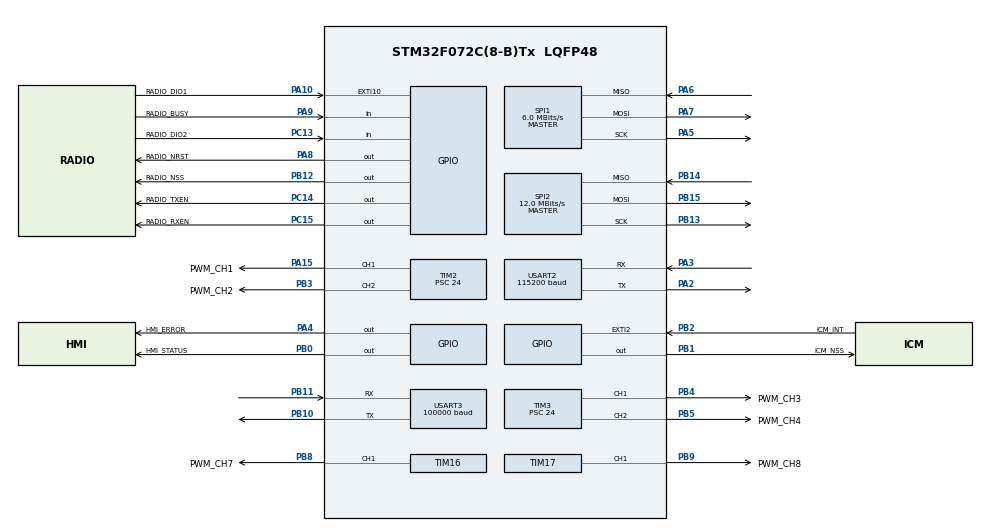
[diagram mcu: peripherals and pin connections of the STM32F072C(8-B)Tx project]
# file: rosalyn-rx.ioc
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Mcu.Family=STM32F0
Mcu.Name=STM32F072C(8-B)Tx
Mcu.Package=LQFP48
NVIC.EXTI2_3_IRQn=true\:0\:0\:false\:false\:false\:true\:false
NVIC.EXTI4_15_IRQn=true\:0\:0\:false\:false\:false\:true\:false
NVIC.TIM7_IRQn=true\:0\:0\:false\:false\:false\:true\:false
NVIC.USART2_IRQn=true\:0\:0\:false\:false\:false\:true\:false
NVIC.USART3_4_IRQn=true\:0\:0\:false\:false\:false\:true\:false
PA10.GPIO_Label=RADIO_DIO1
PA10.GPIO_PuPd=GPIO_NOPULL
PA10.Signal=GPXTI10
PA13.Mode=Serial_Wire
PA13.Signal=SYS_SWDIO
PA14.Mode=Serial_Wire
PA14.Signal=SYS_SWCLK
PA15.GPIO_Label=PWM_CH1
PA15.Signal=S_TIM2_CH1_ETR
PA2.Mode=Asynchronous
PA2.Signal=USART2_TX
PA3.GPIO_PuPd=GPIO_PULLUP
PA3.Mode=Asynchronous
PA3.Signal=USART2_RX
PA4.GPIO_Label=HMI_ERROR
PA4.PinState=GPIO_PIN_SET
PA4.Signal=GPIO_Output
PA5.Mode=Full_Duplex_Master
PA5.Signal=SPI1_SCK
PA6.GPIO_PuPd=GPIO_PULLUP
PA6.Mode=Full_Duplex_Master
PA6.Signal=SPI1_MISO
PA7.Mode=Full_Duplex_Master
PA7.Signal=SPI1_MOSI
PA8.GPIO_Label=RADIO_NRST
PA8.PinState=GPIO_PIN_SET
PA8.Signal=GPIO_Output
PA9.GPIO_Label=RADIO_BUSY
PA9.GPIO_PuPd=GPIO_NOPULL
PA9.Signal=GPIO_Input
PB0.GPIO_Label=HMI_STATUS
PB0.PinState=GPIO_PIN_SET
PB0.Signal=GPIO_Output
PB1.GPIO_Label=ICM_NSS
PB1.PinState=GPIO_PIN_SET
PB1.Signal=GPIO_Output
PB10.Mode=Asynchronous
PB10.Signal=USART3_TX
PB11.GPIO_PuPd=GPIO_PULLUP
PB11.Mode=Asynchronous
PB11.Signal=USART3_RX
PB12.GPIO_Label=RADIO_NSS
PB12.PinState=GPIO_PIN_SET
PB12.Signal=GPIO_Output
PB13.Mode=Full_Duplex_Master
PB13.Signal=SPI2_SCK
PB14.GPIO_PuPd=GPIO_PULLUP
PB14.Mode=Full_Duplex_Master
PB14.Signal=SPI2_MISO
PB15.Mode=Full_Duplex_Master
PB15.Signal=SPI2_MOSI
PB2.GPIO_Label=ICM_INT
PB2.GPIO_PuPd=GPIO_PULLDOWN
PB2.Signal=GPXTI2
PB3.GPIO_Label=PWM_CH2
PB3.Signal=S_TIM2_CH2
PB4.GPIO_Label=PWM_CH3
PB4.Signal=S_TIM3_CH1
PB5.GPIO_Label=PWM_CH4
PB5.Signal=S_TIM3_CH2
PB8.GPIO_Label=PWM_CH7
PB8.Signal=S_TIM16_CH1
PB9.GPIO_Label=PWM_CH8
PB9.Signal=S_TIM17_CH1
PC13.GPIO_Label=RADIO_DIO2
PC13.GPIO_PuPd=GPIO_NOPULL
PC13.Signal=GPIO_Input
PC14-OSC32_IN.GPIO_Label=RADIO_TXEN
PC14-OSC32_IN.Signal=GPIO_Output
PC15-OSC32_OUT.GPIO_Label=RADIO_RXEN
PC15-OSC32_OUT.Signal=GPIO_Output
ProjectManager.HeapSize=0x200
ProjectManager.StackSize=0x400
ProjectManager.TargetToolchain=STM32CubeIDE
RCC.AHBFreq_Value=48000000
RCC.APB1Freq_Value=48000000
RCC.APB1TimFreq_Value=48000000
RCC.HCLKFreq_Value=48000000
RCC.SYSCLKFreq_VALUE=48000000
RCC.SYSCLKSource=RCC_SYSCLKSOURCE_HSI48
SH.S_TIM16_CH1.0=TIM16_CH1,PWM Generation1 CH1
SH.S_TIM17_CH1.0=TIM17_CH1,PWM Generation1 CH1
SH.S_TIM2_CH1_ETR.0=TIM2_CH1,PWM Generation1 CH1
SH.S_TIM2_CH2.0=TIM2_CH2,PWM Generation2 CH2
SH.S_TIM3_CH1.0=TIM3_CH1,PWM Generation1 CH1
SH.S_TIM3_CH2.0=TIM3_CH2,PWM Generation2 CH2
SPI1.BaudRatePrescaler=SPI_BAUDRATEPRESCALER_8
SPI1.CalculateBaudRate=6.0 MBits/s
SPI1.DataSize=SPI_DATASIZE_8BIT
SPI1.Direction=SPI_DIRECTION_2LINES
SPI1.Mode=SPI_MODE_MASTER
SPI1.VirtualType=VM_MASTER
SPI2.BaudRatePrescaler=SPI_BAUDRATEPRESCALER_4
SPI2.CalculateBaudRate=12.0 MBits/s
SPI2.DataSize=SPI_DATASIZE_8BIT
SPI2.Direction=SPI_DIRECTION_2LINES
SPI2.Mode=SPI_MODE_MASTER
SPI2.VirtualType=VM_MASTER
TIM16.AutomaticOutput=TIM_AUTOMATICOUTPUT_ENABLE
TIM16.Channel=TIM_CHANNEL_1
TIM16.Period=39999
TIM16.Prescaler=24
TIM16.Pulse=0
TIM17.AutomaticOutput=TIM_AUTOMATICOUTPUT_ENABLE
TIM17.Channel=TIM_CHANNEL_1
TIM17.OffStateIDLEMode=TIM_OSSI_DISABLE
TIM17.Period=39999
TIM17.Prescaler=24
TIM17.Pulse=0
TIM2.Channel-PWM\ Generation1\ CH1=TIM_CHANNEL_1
TIM2.Channel-PWM\ Generation2\ CH2=TIM_CHANNEL_2
TIM2.Period=39999
TIM2.Prescaler=24
TIM2.Pulse-PWM\ Generation1\ CH1=0
TIM2.Pulse-PWM\ Generation2\ CH2=0
TIM3.Channel-PWM\ Generation1\ CH1=TIM_CHANNEL_1
TIM3.Channel-PWM\ Generation2\ CH2=TIM_CHANNEL_2
TIM3.Period=39999
TIM3.Prescaler=24
TIM3.Pulse-PWM\ Generation1\ CH1=0
TIM3.Pulse-PWM\ Generation2\ CH2=0
TIM7.Period=30000
TIM7.Prescaler=48
USART2.BaudRate=115200
USART2.VirtualMode-Asynchronous=VM_ASYNC
USART3.BaudRate=100000
USART3.Parity=PARITY_EVEN
USART3.RxPinLevelInvertParam=ADVFEATURE_RXINV_ENABLE
USART3.StopBits=STOPBITS_2
USART3.TxPinLevelInvertParam=ADVFEATURE_TXINV_ENABLE
USART3.VirtualMode-Asynchronous=VM_ASYNC
USART3.WordLength=WORDLENGTH_9B
VP_CRC_VS_CRC.Mode=CRC_Activate
VP_TIM16_VS_ClockSourceINT.Mode=Enable_Timer
VP_TIM17_VS_ClockSourceINT.Mode=Enable_Timer
VP_TIM2_VS_ClockSourceINT.Mode=Internal
VP_TIM3_VS_ClockSourceINT.Mode=Internal
VP_TIM7_VS_ClockSourceINT.Mode=Enable_Timer
board=custom

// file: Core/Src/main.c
/* USER CODE BEGIN Header */
/**
  ******************************************************************************
  * @file           : main.c
  * @brief          : Main program body
  ******************************************************************************
  * @attention
  *
  * <h2><center>&copy; Copyright (c) 2020 STMicroelectronics.
  * All rights reserved.</center></h2>
  *
  * This software component is licensed by ST under BSD 3-Clause license,
  * the "License"; You may not use this file except in compliance with the
  * License. You may obtain a copy of the License at:
  *                        opensource.org/licenses/BSD-3-Clause
  *
  ******************************************************************************
  */
/* USER CODE END Header */
#include "main.h"

void SystemClock_Config(void);
static void MX_GPIO_Init(void);
static void MX_SPI2_Init(void);
static void MX_CRC_Init(void);
static void MX_SPI1_Init(void);
static void MX_USART2_UART_Init(void);
static void MX_USART3_UART_Init(void);
static void MX_TIM2_Init(void);
static void MX_TIM3_Init(void);
static void MX_TIM16_Init(void);
static void MX_TIM17_Init(void);
static void MX_TIM7_Init(void);

int main(void)
{

  /* MCU Configuration--------------------------------------------------------*/

  /* Reset of all peripherals, Initializes the Flash interface and the Systick. */

  LL_APB1_GRP2_EnableClock(LL_APB1_GRP2_PERIPH_SYSCFG);
  LL_APB1_GRP1_EnableClock(LL_APB1_GRP1_PERIPH_PWR);

  /* System interrupt init*/

  /* Configure the system clock */
  SystemClock_Config();

  /* Initialize all configured peripherals */
  MX_GPIO_Init();
  MX_SPI2_Init();
  MX_CRC_Init();
  MX_SPI1_Init();
  MX_USART2_UART_Init();
  MX_USART3_UART_Init();
  MX_TIM2_Init();
  MX_TIM3_Init();
  MX_TIM16_Init();
  MX_TIM17_Init();
  MX_TIM7_Init();
  /* USER CODE BEGIN 2 */
  extern void RosalynRxSetup( void );
  RosalynRxSetup();
  /* USER CODE END 2 */

  /* Infinite loop */
  while (1)
  {

    /* USER CODE BEGIN 3 */
    extern void RosalynRxLoop( void );
    RosalynRxLoop();
  }
  /* USER CODE END 3 */
}

void SystemClock_Config(void)
{
  LL_FLASH_SetLatency(LL_FLASH_LATENCY_1);
  while(LL_FLASH_GetLatency() != LL_FLASH_LATENCY_1)
  {
  }
  LL_RCC_HSI48_Enable();

   /* Wait till HSI48 is ready */
  while(LL_RCC_HSI48_IsReady() != 1)
  {

  }
  LL_RCC_SetAHBPrescaler(LL_RCC_SYSCLK_DIV_1);
  LL_RCC_SetAPB1Prescaler(LL_RCC_APB1_DIV_1);
  LL_RCC_SetSysClkSource(LL_RCC_SYS_CLKSOURCE_HSI48);

   /* Wait till System clock is ready */
  while(LL_RCC_GetSysClkSource() != LL_RCC_SYS_CLKSOURCE_STATUS_HSI48)
  {

  }
  LL_Init1msTick(48000000);
  LL_SetSystemCoreClock(48000000);
  LL_RCC_SetUSARTClockSource(LL_RCC_USART2_CLKSOURCE_PCLK1);
}

static void MX_CRC_Init(void)
{

  /* Peripheral clock enable */
  LL_AHB1_GRP1_EnableClock(LL_AHB1_GRP1_PERIPH_CRC);

  LL_CRC_SetInputDataReverseMode(CRC, LL_CRC_INDATA_REVERSE_NONE);
  LL_CRC_SetOutputDataReverseMode(CRC, LL_CRC_OUTDATA_REVERSE_NONE);
  LL_CRC_SetInitialData(CRC, LL_CRC_DEFAULT_CRC_INITVALUE);

}

static void MX_SPI1_Init(void)
{

  LL_SPI_InitTypeDef SPI_InitStruct = {0};

  LL_GPIO_InitTypeDef GPIO_InitStruct = {0};

  /* Peripheral clock enable */
  LL_APB1_GRP2_EnableClock(LL_APB1_GRP2_PERIPH_SPI1);

  LL_AHB1_GRP1_EnableClock(LL_AHB1_GRP1_PERIPH_GPIOA);
  /**SPI1 GPIO Configuration
  PA5   ------> SPI1_SCK
  PA6   ------> SPI1_MISO
  PA7   ------> SPI1_MOSI
  */
  GPIO_InitStruct.Pin = LL_GPIO_PIN_5;
  GPIO_InitStruct.Mode = LL_GPIO_MODE_ALTERNATE;
  GPIO_InitStruct.Speed = LL_GPIO_SPEED_FREQ_HIGH;
  GPIO_InitStruct.OutputType = LL_GPIO_OUTPUT_PUSHPULL;
  GPIO_InitStruct.Pull = LL_GPIO_PULL_NO;
  GPIO_InitStruct.Alternate = LL_GPIO_AF_0;
  LL_GPIO_Init(GPIOA, &GPIO_InitStruct);

  GPIO_InitStruct.Pin = LL_GPIO_PIN_6;
  GPIO_InitStruct.Mode = LL_GPIO_MODE_ALTERNATE;
  GPIO_InitStruct.Speed = LL_GPIO_SPEED_FREQ_HIGH;
  GPIO_InitStruct.OutputType = LL_GPIO_OUTPUT_PUSHPULL;
  GPIO_InitStruct.Pull = LL_GPIO_PULL_UP;
  GPIO_InitStruct.Alternate = LL_GPIO_AF_0;
  LL_GPIO_Init(GPIOA, &GPIO_InitStruct);

  GPIO_InitStruct.Pin = LL_GPIO_PIN_7;
  GPIO_InitStruct.Mode = LL_GPIO_MODE_ALTERNATE;
  GPIO_InitStruct.Speed = LL_GPIO_SPEED_FREQ_HIGH;
  GPIO_InitStruct.OutputType = LL_GPIO_OUTPUT_PUSHPULL;
  GPIO_InitStruct.Pull = LL_GPIO_PULL_NO;
  GPIO_InitStruct.Alternate = LL_GPIO_AF_0;
  LL_GPIO_Init(GPIOA, &GPIO_InitStruct);

  /* SPI1 parameter configuration*/
  SPI_InitStruct.TransferDirection = LL_SPI_FULL_DUPLEX;
  SPI_InitStruct.Mode = LL_SPI_MODE_MASTER;
  SPI_InitStruct.DataWidth = LL_SPI_DATAWIDTH_8BIT;
  SPI_InitStruct.ClockPolarity = LL_SPI_POLARITY_LOW;
  SPI_InitStruct.ClockPhase = LL_SPI_PHASE_1EDGE;
  SPI_InitStruct.NSS = LL_SPI_NSS_SOFT;
  SPI_InitStruct.BaudRate = LL_SPI_BAUDRATEPRESCALER_DIV8;
  SPI_InitStruct.BitOrder = LL_SPI_MSB_FIRST;
  SPI_InitStruct.CRCCalculation = LL_SPI_CRCCALCULATION_DISABLE;
  SPI_InitStruct.CRCPoly = 7;
  LL_SPI_Init(SPI1, &SPI_InitStruct);
  LL_SPI_SetStandard(SPI1, LL_SPI_PROTOCOL_MOTOROLA);
  LL_SPI_EnableNSSPulseMgt(SPI1);

}

static void MX_SPI2_Init(void)
{

  LL_SPI_InitTypeDef SPI_InitStruct = {0};

  LL_GPIO_InitTypeDef GPIO_InitStruct = {0};

  /* Peripheral clock enable */
  LL_APB1_GRP1_EnableClock(LL_APB1_GRP1_PERIPH_SPI2);

  LL_AHB1_GRP1_EnableClock(LL_AHB1_GRP1_PERIPH_GPIOB);
  /**SPI2 GPIO Configuration
  PB13   ------> SPI2_SCK
  PB14   ------> SPI2_MISO
  PB15   ------> SPI2_MOSI
  */
  GPIO_InitStruct.Pin = LL_GPIO_PIN_13;
  GPIO_InitStruct.Mode = LL_GPIO_MODE_ALTERNATE;
  GPIO_InitStruct.Speed = LL_GPIO_SPEED_FREQ_HIGH;
  GPIO_InitStruct.OutputType = LL_GPIO_OUTPUT_PUSHPULL;
  GPIO_InitStruct.Pull = LL_GPIO_PULL_NO;
  GPIO_InitStruct.Alternate = LL_GPIO_AF_0;
  LL_GPIO_Init(GPIOB, &GPIO_InitStruct);

  GPIO_InitStruct.Pin = LL_GPIO_PIN_14;
  GPIO_InitStruct.Mode = LL_GPIO_MODE_ALTERNATE;
  GPIO_InitStruct.Speed = LL_GPIO_SPEED_FREQ_HIGH;
  GPIO_InitStruct.OutputType = LL_GPIO_OUTPUT_PUSHPULL;
  GPIO_InitStruct.Pull = LL_GPIO_PULL_UP;
  GPIO_InitStruct.Alternate = LL_GPIO_AF_0;
  LL_GPIO_Init(GPIOB, &GPIO_InitStruct);

  GPIO_InitStruct.Pin = LL_GPIO_PIN_15;
  GPIO_InitStruct.Mode = LL_GPIO_MODE_ALTERNATE;
  GPIO_InitStruct.Speed = LL_GPIO_SPEED_FREQ_HIGH;
  GPIO_InitStruct.OutputType = LL_GPIO_OUTPUT_PUSHPULL;
  GPIO_InitStruct.Pull = LL_GPIO_PULL_NO;
  GPIO_InitStruct.Alternate = LL_GPIO_AF_0;
  LL_GPIO_Init(GPIOB, &GPIO_InitStruct);

  /* SPI2 parameter configuration*/
  SPI_InitStruct.TransferDirection = LL_SPI_FULL_DUPLEX;
  SPI_InitStruct.Mode = LL_SPI_MODE_MASTER;
  SPI_InitStruct.DataWidth = LL_SPI_DATAWIDTH_8BIT;
  SPI_InitStruct.ClockPolarity = LL_SPI_POLARITY_LOW;
  SPI_InitStruct.ClockPhase = LL_SPI_PHASE_1EDGE;
  SPI_InitStruct.NSS = LL_SPI_NSS_SOFT;
  SPI_InitStruct.BaudRate = LL_SPI_BAUDRATEPRESCALER_DIV4;
  SPI_InitStruct.BitOrder = LL_SPI_MSB_FIRST;
  SPI_InitStruct.CRCCalculation = LL_SPI_CRCCALCULATION_DISABLE;
  SPI_InitStruct.CRCPoly = 7;
  LL_SPI_Init(SPI2, &SPI_InitStruct);
  LL_SPI_SetStandard(SPI2, LL_SPI_PROTOCOL_MOTOROLA);
  LL_SPI_EnableNSSPulseMgt(SPI2);

}

static void MX_TIM2_Init(void)
{

  LL_TIM_InitTypeDef TIM_InitStruct = {0};
  LL_TIM_OC_InitTypeDef TIM_OC_InitStruct = {0};

  LL_GPIO_InitTypeDef GPIO_InitStruct = {0};

  /* Peripheral clock enable */
  LL_APB1_GRP1_EnableClock(LL_APB1_GRP1_PERIPH_TIM2);

  TIM_InitStruct.Prescaler = 24;
  TIM_InitStruct.CounterMode = LL_TIM_COUNTERMODE_UP;
  TIM_InitStruct.Autoreload = 39999;
  TIM_InitStruct.ClockDivision = LL_TIM_CLOCKDIVISION_DIV1;
  LL_TIM_Init(TIM2, &TIM_InitStruct);
  LL_TIM_DisableARRPreload(TIM2);
  LL_TIM_SetClockSource(TIM2, LL_TIM_CLOCKSOURCE_INTERNAL);
  LL_TIM_OC_EnablePreload(TIM2, LL_TIM_CHANNEL_CH1);
  TIM_OC_InitStruct.OCMode = LL_TIM_OCMODE_PWM1;
  TIM_OC_InitStruct.OCState = LL_TIM_OCSTATE_DISABLE;
  TIM_OC_InitStruct.OCNState = LL_TIM_OCSTATE_DISABLE;
  TIM_OC_InitStruct.CompareValue = 0;
  TIM_OC_InitStruct.OCPolarity = LL_TIM_OCPOLARITY_HIGH;
  LL_TIM_OC_Init(TIM2, LL_TIM_CHANNEL_CH1, &TIM_OC_InitStruct);
  LL_TIM_OC_DisableFast(TIM2, LL_TIM_CHANNEL_CH1);
  LL_TIM_OC_EnablePreload(TIM2, LL_TIM_CHANNEL_CH2);
  TIM_OC_InitStruct.OCState = LL_TIM_OCSTATE_DISABLE;
  TIM_OC_InitStruct.OCNState = LL_TIM_OCSTATE_DISABLE;
  LL_TIM_OC_Init(TIM2, LL_TIM_CHANNEL_CH2, &TIM_OC_InitStruct);
  LL_TIM_OC_DisableFast(TIM2, LL_TIM_CHANNEL_CH2);
  LL_TIM_SetTriggerOutput(TIM2, LL_TIM_TRGO_RESET);
  LL_TIM_DisableMasterSlaveMode(TIM2);
  LL_AHB1_GRP1_EnableClock(LL_AHB1_GRP1_PERIPH_GPIOA);
  LL_AHB1_GRP1_EnableClock(LL_AHB1_GRP1_PERIPH_GPIOB);
  /**TIM2 GPIO Configuration
  PA15   ------> TIM2_CH1
  PB3   ------> TIM2_CH2
  */
  GPIO_InitStruct.Pin = PWM_CH1_Pin;
  GPIO_InitStruct.Mode = LL_GPIO_MODE_ALTERNATE;
  GPIO_InitStruct.Speed = LL_GPIO_SPEED_FREQ_LOW;
  GPIO_InitStruct.OutputType = LL_GPIO_OUTPUT_PUSHPULL;
  GPIO_InitStruct.Pull = LL_GPIO_PULL_NO;
  GPIO_InitStruct.Alternate = LL_GPIO_AF_2;
  LL_GPIO_Init(PWM_CH1_GPIO_Port, &GPIO_InitStruct);

  GPIO_InitStruct.Pin = PWM_CH2_Pin;
  GPIO_InitStruct.Mode = LL_GPIO_MODE_ALTERNATE;
  GPIO_InitStruct.Speed = LL_GPIO_SPEED_FREQ_LOW;
  GPIO_InitStruct.OutputType = LL_GPIO_OUTPUT_PUSHPULL;
  GPIO_InitStruct.Pull = LL_GPIO_PULL_NO;
  GPIO_InitStruct.Alternate = LL_GPIO_AF_2;
  LL_GPIO_Init(PWM_CH2_GPIO_Port, &GPIO_InitStruct);

}

static void MX_TIM3_Init(void)
{

  LL_TIM_InitTypeDef TIM_InitStruct = {0};
  LL_TIM_OC_InitTypeDef TIM_OC_InitStruct = {0};

  LL_GPIO_InitTypeDef GPIO_InitStruct = {0};

  /* Peripheral clock enable */
  LL_APB1_GRP1_EnableClock(LL_APB1_GRP1_PERIPH_TIM3);

  TIM_InitStruct.Prescaler = 24;
  TIM_InitStruct.CounterMode = LL_TIM_COUNTERMODE_UP;
  TIM_InitStruct.Autoreload = 39999;
  TIM_InitStruct.ClockDivision = LL_TIM_CLOCKDIVISION_DIV1;
  LL_TIM_Init(TIM3, &TIM_InitStruct);
  LL_TIM_DisableARRPreload(TIM3);
  LL_TIM_SetClockSource(TIM3, LL_TIM_CLOCKSOURCE_INTERNAL);
  LL_TIM_OC_EnablePreload(TIM3, LL_TIM_CHANNEL_CH1);
  TIM_OC_InitStruct.OCMode = LL_TIM_OCMODE_PWM1;
  TIM_OC_InitStruct.OCState = LL_TIM_OCSTATE_DISABLE;
  TIM_OC_InitStruct.OCNState = LL_TIM_OCSTATE_DISABLE;
  TIM_OC_InitStruct.CompareValue = 0;
  TIM_OC_InitStruct.OCPolarity = LL_TIM_OCPOLARITY_HIGH;
  LL_TIM_OC_Init(TIM3, LL_TIM_CHANNEL_CH1, &TIM_OC_InitStruct);
  LL_TIM_OC_DisableFast(TIM3, LL_TIM_CHANNEL_CH1);
  LL_TIM_OC_EnablePreload(TIM3, LL_TIM_CHANNEL_CH2);
  TIM_OC_InitStruct.OCState = LL_TIM_OCSTATE_DISABLE;
  TIM_OC_InitStruct.OCNState = LL_TIM_OCSTATE_DISABLE;
  LL_TIM_OC_Init(TIM3, LL_TIM_CHANNEL_CH2, &TIM_OC_InitStruct);
  LL_TIM_OC_DisableFast(TIM3, LL_TIM_CHANNEL_CH2);
  LL_TIM_SetTriggerOutput(TIM3, LL_TIM_TRGO_RESET);
  LL_TIM_DisableMasterSlaveMode(TIM3);
  LL_AHB1_GRP1_EnableClock(LL_AHB1_GRP1_PERIPH_GPIOB);
  /**TIM3 GPIO Configuration
  PB4   ------> TIM3_CH1
  PB5   ------> TIM3_CH2
  */
  GPIO_InitStruct.Pin = PWM_CH3_Pin;
  GPIO_InitStruct.Mode = LL_GPIO_MODE_ALTERNATE;
  GPIO_InitStruct.Speed = LL_GPIO_SPEED_FREQ_LOW;
  GPIO_InitStruct.OutputType = LL_GPIO_OUTPUT_PUSHPULL;
  GPIO_InitStruct.Pull = LL_GPIO_PULL_NO;
  GPIO_InitStruct.Alternate = LL_GPIO_AF_1;
  LL_GPIO_Init(PWM_CH3_GPIO_Port, &GPIO_InitStruct);

  GPIO_InitStruct.Pin = PWM_CH4_Pin;
  GPIO_InitStruct.Mode = LL_GPIO_MODE_ALTERNATE;
  GPIO_InitStruct.Speed = LL_GPIO_SPEED_FREQ_LOW;
  GPIO_InitStruct.OutputType = LL_GPIO_OUTPUT_PUSHPULL;
  GPIO_InitStruct.Pull = LL_GPIO_PULL_NO;
  GPIO_InitStruct.Alternate = LL_GPIO_AF_1;
  LL_GPIO_Init(PWM_CH4_GPIO_Port, &GPIO_InitStruct);

}

static void MX_TIM7_Init(void)
{

  LL_TIM_InitTypeDef TIM_InitStruct = {0};

  /* Peripheral clock enable */
  LL_APB1_GRP1_EnableClock(LL_APB1_GRP1_PERIPH_TIM7);

  /* TIM7 interrupt Init */
  NVIC_SetPriority(TIM7_IRQn, 0);
  NVIC_EnableIRQ(TIM7_IRQn);

  TIM_InitStruct.Prescaler = 48;
  TIM_InitStruct.CounterMode = LL_TIM_COUNTERMODE_UP;
  TIM_InitStruct.Autoreload = 30000;
  LL_TIM_Init(TIM7, &TIM_InitStruct);
  LL_TIM_DisableARRPreload(TIM7);
  LL_TIM_SetTriggerOutput(TIM7, LL_TIM_TRGO_RESET);
  LL_TIM_DisableMasterSlaveMode(TIM7);

}

static void MX_TIM16_Init(void)
{

  LL_TIM_InitTypeDef TIM_InitStruct = {0};
  LL_TIM_OC_InitTypeDef TIM_OC_InitStruct = {0};
  LL_TIM_BDTR_InitTypeDef TIM_BDTRInitStruct = {0};

  LL_GPIO_InitTypeDef GPIO_InitStruct = {0};

  /* Peripheral clock enable */
  LL_APB1_GRP2_EnableClock(LL_APB1_GRP2_PERIPH_TIM16);

  TIM_InitStruct.Prescaler = 24;
  TIM_InitStruct.CounterMode = LL_TIM_COUNTERMODE_UP;
  TIM_InitStruct.Autoreload = 39999;
  TIM_InitStruct.ClockDivision = LL_TIM_CLOCKDIVISION_DIV1;
  TIM_InitStruct.RepetitionCounter = 0;
  LL_TIM_Init(TIM16, &TIM_InitStruct);
  LL_TIM_DisableARRPreload(TIM16);
  LL_TIM_OC_EnablePreload(TIM16, LL_TIM_CHANNEL_CH1);
  TIM_OC_InitStruct.OCMode = LL_TIM_OCMODE_PWM1;
  TIM_OC_InitStruct.OCState = LL_TIM_OCSTATE_DISABLE;
  TIM_OC_InitStruct.OCNState = LL_TIM_OCSTATE_DISABLE;
  TIM_OC_InitStruct.CompareValue = 0;
  TIM_OC_InitStruct.OCPolarity = LL_TIM_OCPOLARITY_HIGH;
  TIM_OC_InitStruct.OCNPolarity = LL_TIM_OCPOLARITY_HIGH;
  TIM_OC_InitStruct.OCIdleState = LL_TIM_OCIDLESTATE_LOW;
  TIM_OC_InitStruct.OCNIdleState = LL_TIM_OCIDLESTATE_LOW;
  LL_TIM_OC_Init(TIM16, LL_TIM_CHANNEL_CH1, &TIM_OC_InitStruct);
  LL_TIM_OC_DisableFast(TIM16, LL_TIM_CHANNEL_CH1);
  TIM_BDTRInitStruct.OSSRState = LL_TIM_OSSR_DISABLE;
  TIM_BDTRInitStruct.OSSIState = LL_TIM_OSSI_DISABLE;
  TIM_BDTRInitStruct.LockLevel = LL_TIM_LOCKLEVEL_OFF;
  TIM_BDTRInitStruct.DeadTime = 0;
  TIM_BDTRInitStruct.BreakState = LL_TIM_BREAK_DISABLE;
  TIM_BDTRInitStruct.BreakPolarity = LL_TIM_BREAK_POLARITY_HIGH;
  TIM_BDTRInitStruct.AutomaticOutput = LL_TIM_AUTOMATICOUTPUT_ENABLE;
  LL_TIM_BDTR_Init(TIM16, &TIM_BDTRInitStruct);
  LL_AHB1_GRP1_EnableClock(LL_AHB1_GRP1_PERIPH_GPIOB);
  /**TIM16 GPIO Configuration
  PB8   ------> TIM16_CH1
  */
  GPIO_InitStruct.Pin = PWM_CH7_Pin;
  GPIO_InitStruct.Mode = LL_GPIO_MODE_ALTERNATE;
  GPIO_InitStruct.Speed = LL_GPIO_SPEED_FREQ_LOW;
  GPIO_InitStruct.OutputType = LL_GPIO_OUTPUT_PUSHPULL;
  GPIO_InitStruct.Pull = LL_GPIO_PULL_NO;
  GPIO_InitStruct.Alternate = LL_GPIO_AF_2;
  LL_GPIO_Init(PWM_CH7_GPIO_Port, &GPIO_InitStruct);

}

static void MX_TIM17_Init(void)
{

  LL_TIM_InitTypeDef TIM_InitStruct = {0};
  LL_TIM_OC_InitTypeDef TIM_OC_InitStruct = {0};
  LL_TIM_BDTR_InitTypeDef TIM_BDTRInitStruct = {0};

  LL_GPIO_InitTypeDef GPIO_InitStruct = {0};

  /* Peripheral clock enable */
  LL_APB1_GRP2_EnableClock(LL_APB1_GRP2_PERIPH_TIM17);

  TIM_InitStruct.Prescaler = 24;
  TIM_InitStruct.CounterMode = LL_TIM_COUNTERMODE_UP;
  TIM_InitStruct.Autoreload = 39999;
  TIM_InitStruct.ClockDivision = LL_TIM_CLOCKDIVISION_DIV1;
  TIM_InitStruct.RepetitionCounter = 0;
  LL_TIM_Init(TIM17, &TIM_InitStruct);
  LL_TIM_DisableARRPreload(TIM17);
  LL_TIM_OC_EnablePreload(TIM17, LL_TIM_CHANNEL_CH1);
  TIM_OC_InitStruct.OCMode = LL_TIM_OCMODE_PWM1;
  TIM_OC_InitStruct.OCState = LL_TIM_OCSTATE_DISABLE;
  TIM_OC_InitStruct.OCNState = LL_TIM_OCSTATE_DISABLE;
  TIM_OC_InitStruct.CompareValue = 0;
  TIM_OC_InitStruct.OCPolarity = LL_TIM_OCPOLARITY_HIGH;
  TIM_OC_InitStruct.OCNPolarity = LL_TIM_OCPOLARITY_HIGH;
  TIM_OC_InitStruct.OCIdleState = LL_TIM_OCIDLESTATE_LOW;
  TIM_OC_InitStruct.OCNIdleState = LL_TIM_OCIDLESTATE_LOW;
  LL_TIM_OC_Init(TIM17, LL_TIM_CHANNEL_CH1, &TIM_OC_InitStruct);
  LL_TIM_OC_DisableFast(TIM17, LL_TIM_CHANNEL_CH1);
  TIM_BDTRInitStruct.OSSRState = LL_TIM_OSSR_DISABLE;
  TIM_BDTRInitStruct.OSSIState = LL_TIM_OSSI_DISABLE;
  TIM_BDTRInitStruct.LockLevel = LL_TIM_LOCKLEVEL_OFF;
  TIM_BDTRInitStruct.DeadTime = 0;
  TIM_BDTRInitStruct.BreakState = LL_TIM_BREAK_DISABLE;
  TIM_BDTRInitStruct.BreakPolarity = LL_TIM_BREAK_POLARITY_HIGH;
  TIM_BDTRInitStruct.AutomaticOutput = LL_TIM_AUTOMATICOUTPUT_ENABLE;
  LL_TIM_BDTR_Init(TIM17, &TIM_BDTRInitStruct);
  LL_AHB1_GRP1_EnableClock(LL_AHB1_GRP1_PERIPH_GPIOB);
  /**TIM17 GPIO Configuration
  PB9   ------> TIM17_CH1
  */
  GPIO_InitStruct.Pin = PWM_CH8_Pin;
  GPIO_InitStruct.Mode = LL_GPIO_MODE_ALTERNATE;
  GPIO_InitStruct.Speed = LL_GPIO_SPEED_FREQ_LOW;
  GPIO_InitStruct.OutputType = LL_GPIO_OUTPUT_PUSHPULL;
  GPIO_InitStruct.Pull = LL_GPIO_PULL_NO;
  GPIO_InitStruct.Alternate = LL_GPIO_AF_2;
  LL_GPIO_Init(PWM_CH8_GPIO_Port, &GPIO_InitStruct);

}

static void MX_USART2_UART_Init(void)
{

  LL_USART_InitTypeDef USART_InitStruct = {0};

  LL_GPIO_InitTypeDef GPIO_InitStruct = {0};

  /* Peripheral clock enable */
  LL_APB1_GRP1_EnableClock(LL_APB1_GRP1_PERIPH_USART2);

  LL_AHB1_GRP1_EnableClock(LL_AHB1_GRP1_PERIPH_GPIOA);
  /**USART2 GPIO Configuration
  PA2   ------> USART2_TX
  PA3   ------> USART2_RX
  */
  GPIO_InitStruct.Pin = LL_GPIO_PIN_2;
  GPIO_InitStruct.Mode = LL_GPIO_MODE_ALTERNATE;
  GPIO_InitStruct.Speed = LL_GPIO_SPEED_FREQ_HIGH;
  GPIO_InitStruct.OutputType = LL_GPIO_OUTPUT_PUSHPULL;
  GPIO_InitStruct.Pull = LL_GPIO_PULL_NO;
  GPIO_InitStruct.Alternate = LL_GPIO_AF_1;
  LL_GPIO_Init(GPIOA, &GPIO_InitStruct);

  GPIO_InitStruct.Pin = LL_GPIO_PIN_3;
  GPIO_InitStruct.Mode = LL_GPIO_MODE_ALTERNATE;
  GPIO_InitStruct.Speed = LL_GPIO_SPEED_FREQ_HIGH;
  GPIO_InitStruct.OutputType = LL_GPIO_OUTPUT_PUSHPULL;
  GPIO_InitStruct.Pull = LL_GPIO_PULL_UP;
  GPIO_InitStruct.Alternate = LL_GPIO_AF_1;
  LL_GPIO_Init(GPIOA, &GPIO_InitStruct);

  /* USART2 interrupt Init */
  NVIC_SetPriority(USART2_IRQn, 0);
  NVIC_EnableIRQ(USART2_IRQn);

  USART_InitStruct.BaudRate = 115200;
  USART_InitStruct.DataWidth = LL_USART_DATAWIDTH_8B;
  USART_InitStruct.StopBits = LL_USART_STOPBITS_1;
  USART_InitStruct.Parity = LL_USART_PARITY_NONE;
  USART_InitStruct.TransferDirection = LL_USART_DIRECTION_TX_RX;
  USART_InitStruct.HardwareFlowControl = LL_USART_HWCONTROL_NONE;
  USART_InitStruct.OverSampling = LL_USART_OVERSAMPLING_16;
  LL_USART_Init(USART2, &USART_InitStruct);
  LL_USART_DisableIT_CTS(USART2);
  LL_USART_ConfigAsyncMode(USART2);
  LL_USART_Enable(USART2);

}

static void MX_USART3_UART_Init(void)
{

  LL_USART_InitTypeDef USART_InitStruct = {0};

  LL_GPIO_InitTypeDef GPIO_InitStruct = {0};

  /* Peripheral clock enable */
  LL_APB1_GRP1_EnableClock(LL_APB1_GRP1_PERIPH_USART3);

  LL_AHB1_GRP1_EnableClock(LL_AHB1_GRP1_PERIPH_GPIOB);
  /**USART3 GPIO Configuration
  PB10   ------> USART3_TX
  PB11   ------> USART3_RX
  */
  GPIO_InitStruct.Pin = LL_GPIO_PIN_10;
  GPIO_InitStruct.Mode = LL_GPIO_MODE_ALTERNATE;
  GPIO_InitStruct.Speed = LL_GPIO_SPEED_FREQ_HIGH;
  GPIO_InitStruct.OutputType = LL_GPIO_OUTPUT_PUSHPULL;
  GPIO_InitStruct.Pull = LL_GPIO_PULL_NO;
  GPIO_InitStruct.Alternate = LL_GPIO_AF_4;
  LL_GPIO_Init(GPIOB, &GPIO_InitStruct);

  GPIO_InitStruct.Pin = LL_GPIO_PIN_11;
  GPIO_InitStruct.Mode = LL_GPIO_MODE_ALTERNATE;
  GPIO_InitStruct.Speed = LL_GPIO_SPEED_FREQ_HIGH;
  GPIO_InitStruct.OutputType = LL_GPIO_OUTPUT_PUSHPULL;
  GPIO_InitStruct.Pull = LL_GPIO_PULL_UP;
  GPIO_InitStruct.Alternate = LL_GPIO_AF_4;
  LL_GPIO_Init(GPIOB, &GPIO_InitStruct);

  /* USART3 interrupt Init */
  NVIC_SetPriority(USART3_4_IRQn, 0);
  NVIC_EnableIRQ(USART3_4_IRQn);

  USART_InitStruct.BaudRate = 100000;
  USART_InitStruct.DataWidth = LL_USART_DATAWIDTH_9B;
  USART_InitStruct.StopBits = LL_USART_STOPBITS_2;
  USART_InitStruct.Parity = LL_USART_PARITY_EVEN;
  USART_InitStruct.TransferDirection = LL_USART_DIRECTION_TX_RX;
  USART_InitStruct.HardwareFlowControl = LL_USART_HWCONTROL_NONE;
  USART_InitStruct.OverSampling = LL_USART_OVERSAMPLING_16;
  LL_USART_Init(USART3, &USART_InitStruct);
  LL_USART_DisableIT_CTS(USART3);
  LL_USART_SetRXPinLevel(USART3, LL_USART_RXPIN_LEVEL_INVERTED);
  LL_USART_SetTXPinLevel(USART3, LL_USART_TXPIN_LEVEL_INVERTED);
  LL_USART_ConfigAsyncMode(USART3);
  LL_USART_Enable(USART3);

}

static void MX_GPIO_Init(void)
{
  LL_EXTI_InitTypeDef EXTI_InitStruct = {0};
  LL_GPIO_InitTypeDef GPIO_InitStruct = {0};

  /* GPIO Ports Clock Enable */
  LL_AHB1_GRP1_EnableClock(LL_AHB1_GRP1_PERIPH_GPIOC);
  LL_AHB1_GRP1_EnableClock(LL_AHB1_GRP1_PERIPH_GPIOF);
  LL_AHB1_GRP1_EnableClock(LL_AHB1_GRP1_PERIPH_GPIOA);
  LL_AHB1_GRP1_EnableClock(LL_AHB1_GRP1_PERIPH_GPIOB);

  /**/
  LL_GPIO_ResetOutputPin(RADIO_TXEN_GPIO_Port, RADIO_TXEN_Pin);

  /**/
  LL_GPIO_ResetOutputPin(RADIO_RXEN_GPIO_Port, RADIO_RXEN_Pin);

  /**/
  LL_GPIO_SetOutputPin(HMI_ERROR_GPIO_Port, HMI_ERROR_Pin);

  /**/
  LL_GPIO_SetOutputPin(HMI_STATUS_GPIO_Port, HMI_STATUS_Pin);

  /**/
  LL_GPIO_SetOutputPin(ICM_NSS_GPIO_Port, ICM_NSS_Pin);

  /**/
  LL_GPIO_SetOutputPin(RADIO_NSS_GPIO_Port, RADIO_NSS_Pin);

  /**/
  LL_GPIO_SetOutputPin(RADIO_NRST_GPIO_Port, RADIO_NRST_Pin);

  /**/
  GPIO_InitStruct.Pin = RADIO_DIO2_Pin;
  GPIO_InitStruct.Mode = LL_GPIO_MODE_INPUT;
  GPIO_InitStruct.Pull = LL_GPIO_PULL_NO;
  LL_GPIO_Init(RADIO_DIO2_GPIO_Port, &GPIO_InitStruct);

  /**/
  GPIO_InitStruct.Pin = RADIO_TXEN_Pin;
  GPIO_InitStruct.Mode = LL_GPIO_MODE_OUTPUT;
  GPIO_InitStruct.Speed = LL_GPIO_SPEED_FREQ_LOW;
  GPIO_InitStruct.OutputType = LL_GPIO_OUTPUT_PUSHPULL;
  GPIO_InitStruct.Pull = LL_GPIO_PULL_NO;
  LL_GPIO_Init(RADIO_TXEN_GPIO_Port, &GPIO_InitStruct);

  /**/
  GPIO_InitStruct.Pin = RADIO_RXEN_Pin;
  GPIO_InitStruct.Mode = LL_GPIO_MODE_OUTPUT;
  GPIO_InitStruct.Speed = LL_GPIO_SPEED_FREQ_LOW;
  GPIO_InitStruct.OutputType = LL_GPIO_OUTPUT_PUSHPULL;
  GPIO_InitStruct.Pull = LL_GPIO_PULL_NO;
  LL_GPIO_Init(RADIO_RXEN_GPIO_Port, &GPIO_InitStruct);

  /**/
  GPIO_InitStruct.Pin = LL_GPIO_PIN_0;
  GPIO_InitStruct.Mode = LL_GPIO_MODE_ANALOG;
  GPIO_InitStruct.Pull = LL_GPIO_PULL_NO;
  LL_GPIO_Init(GPIOF, &GPIO_InitStruct);

  /**/
  GPIO_InitStruct.Pin = LL_GPIO_PIN_1;
  GPIO_InitStruct.Mode = LL_GPIO_MODE_ANALOG;
  GPIO_InitStruct.Pull = LL_GPIO_PULL_NO;
  LL_GPIO_Init(GPIOF, &GPIO_InitStruct);

  /**/
  GPIO_InitStruct.Pin = LL_GPIO_PIN_0;
  GPIO_InitStruct.Mode = LL_GPIO_MODE_ANALOG;
  GPIO_InitStruct.Pull = LL_GPIO_PULL_NO;
  LL_GPIO_Init(GPIOA, &GPIO_InitStruct);

  /**/
  GPIO_InitStruct.Pin = LL_GPIO_PIN_1;
  GPIO_InitStruct.Mode = LL_GPIO_MODE_ANALOG;
  GPIO_InitStruct.Pull = LL_GPIO_PULL_NO;
  LL_GPIO_Init(GPIOA, &GPIO_InitStruct);

  /**/
  GPIO_InitStruct.Pin = HMI_ERROR_Pin;
  GPIO_InitStruct.Mode = LL_GPIO_MODE_OUTPUT;
  GPIO_InitStruct.Speed = LL_GPIO_SPEED_FREQ_LOW;
  GPIO_InitStruct.OutputType = LL_GPIO_OUTPUT_PUSHPULL;
  GPIO_InitStruct.Pull = LL_GPIO_PULL_NO;
  LL_GPIO_Init(HMI_ERROR_GPIO_Port, &GPIO_InitStruct);

  /**/
  GPIO_InitStruct.Pin = HMI_STATUS_Pin;
  GPIO_InitStruct.Mode = LL_GPIO_MODE_OUTPUT;
  GPIO_InitStruct.Speed = LL_GPIO_SPEED_FREQ_LOW;
  GPIO_InitStruct.OutputType = LL_GPIO_OUTPUT_PUSHPULL;
  GPIO_InitStruct.Pull = LL_GPIO_PULL_NO;
  LL_GPIO_Init(HMI_STATUS_GPIO_Port, &GPIO_InitStruct);

  /**/
  GPIO_InitStruct.Pin = ICM_NSS_Pin;
  GPIO_InitStruct.Mode = LL_GPIO_MODE_OUTPUT;
  GPIO_InitStruct.Speed = LL_GPIO_SPEED_FREQ_LOW;
  GPIO_InitStruct.OutputType = LL_GPIO_OUTPUT_PUSHPULL;
  GPIO_InitStruct.Pull = LL_GPIO_PULL_NO;
  LL_GPIO_Init(ICM_NSS_GPIO_Port, &GPIO_InitStruct);

  /**/
  GPIO_InitStruct.Pin = RADIO_NSS_Pin;
  GPIO_InitStruct.Mode = LL_GPIO_MODE_OUTPUT;
  GPIO_InitStruct.Speed = LL_GPIO_SPEED_FREQ_LOW;
  GPIO_InitStruct.OutputType = LL_GPIO_OUTPUT_PUSHPULL;
  GPIO_InitStruct.Pull = LL_GPIO_PULL_NO;
  LL_GPIO_Init(RADIO_NSS_GPIO_Port, &GPIO_InitStruct);

  /**/
  GPIO_InitStruct.Pin = RADIO_NRST_Pin;
  GPIO_InitStruct.Mode = LL_GPIO_MODE_OUTPUT;
  GPIO_InitStruct.Speed = LL_GPIO_SPEED_FREQ_LOW;
  GPIO_InitStruct.OutputType = LL_GPIO_OUTPUT_PUSHPULL;
  GPIO_InitStruct.Pull = LL_GPIO_PULL_NO;
  LL_GPIO_Init(RADIO_NRST_GPIO_Port, &GPIO_InitStruct);

  /**/
  GPIO_InitStruct.Pin = RADIO_BUSY_Pin;
  GPIO_InitStruct.Mode = LL_GPIO_MODE_INPUT;
  GPIO_InitStruct.Pull = LL_GPIO_PULL_NO;
  LL_GPIO_Init(RADIO_BUSY_GPIO_Port, &GPIO_InitStruct);

  /**/
  GPIO_InitStruct.Pin = LL_GPIO_PIN_11;
  GPIO_InitStruct.Mode = LL_GPIO_MODE_ANALOG;
  GPIO_InitStruct.Pull = LL_GPIO_PULL_NO;
  LL_GPIO_Init(GPIOA, &GPIO_InitStruct);

  /**/
  GPIO_InitStruct.Pin = LL_GPIO_PIN_12;
  GPIO_InitStruct.Mode = LL_GPIO_MODE_ANALOG;
  GPIO_InitStruct.Pull = LL_GPIO_PULL_NO;
  LL_GPIO_Init(GPIOA, &GPIO_InitStruct);

  /**/
  GPIO_InitStruct.Pin = LL_GPIO_PIN_6;
  GPIO_InitStruct.Mode = LL_GPIO_MODE_ANALOG;
  GPIO_InitStruct.Pull = LL_GPIO_PULL_NO;
  LL_GPIO_Init(GPIOB, &GPIO_InitStruct);

  /**/
  GPIO_InitStruct.Pin = LL_GPIO_PIN_7;
  GPIO_InitStruct.Mode = LL_GPIO_MODE_ANALOG;
  GPIO_InitStruct.Pull = LL_GPIO_PULL_NO;
  LL_GPIO_Init(GPIOB, &GPIO_InitStruct);

  /**/
  LL_SYSCFG_SetEXTISource(LL_SYSCFG_EXTI_PORTB, LL_SYSCFG_EXTI_LINE2);

  /**/
  LL_SYSCFG_SetEXTISource(LL_SYSCFG_EXTI_PORTA, LL_SYSCFG_EXTI_LINE10);

  /**/
  LL_GPIO_SetPinPull(ICM_INT_GPIO_Port, ICM_INT_Pin, LL_GPIO_PULL_DOWN);

  /**/
  LL_GPIO_SetPinPull(RADIO_DIO1_GPIO_Port, RADIO_DIO1_Pin, LL_GPIO_PULL_NO);

  /**/
  LL_GPIO_SetPinMode(ICM_INT_GPIO_Port, ICM_INT_Pin, LL_GPIO_MODE_INPUT);

  /**/
  LL_GPIO_SetPinMode(RADIO_DIO1_GPIO_Port, RADIO_DIO1_Pin, LL_GPIO_MODE_INPUT);

  /**/
  EXTI_InitStruct.Line_0_31 = LL_EXTI_LINE_2;
  EXTI_InitStruct.LineCommand = ENABLE;
  EXTI_InitStruct.Mode = LL_EXTI_MODE_IT;
  EXTI_InitStruct.Trigger = LL_EXTI_TRIGGER_RISING;
  LL_EXTI_Init(&EXTI_InitStruct);

  /**/
  EXTI_InitStruct.Line_0_31 = LL_EXTI_LINE_10;
  EXTI_InitStruct.LineCommand = ENABLE;
  EXTI_InitStruct.Mode = LL_EXTI_MODE_IT;
  EXTI_InitStruct.Trigger = LL_EXTI_TRIGGER_RISING;
  LL_EXTI_Init(&EXTI_InitStruct);

  /* EXTI interrupt init*/
  NVIC_SetPriority(EXTI2_3_IRQn, 0);
  NVIC_EnableIRQ(EXTI2_3_IRQn);
  NVIC_SetPriority(EXTI4_15_IRQn, 0);
  NVIC_EnableIRQ(EXTI4_15_IRQn);

}

void Error_Handler(void)
{
  __disable_irq();
  while (1)
  {
  }
}

/************************ (C) COPYRIGHT STMicroelectronics *****END OF FILE****/
